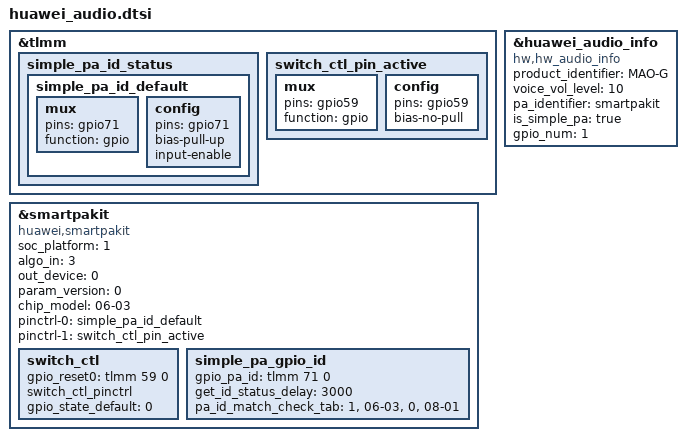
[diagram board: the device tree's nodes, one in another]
&tlmm {
	simple_pa_id_status: simple_pa_id_status {
		simple_pa_id_default: simple_pa_id_default {
			mux {
				pins = "gpio71";
				function = "gpio";
			};

			config {
				pins = "gpio71";
				bias-pull-up;
				input-enable;
			};
		};
	};
	switch_ctl_pin_active: switch_ctl_pin_active {
		mux {
			pins = "gpio59";
			function = "gpio";
		};

		config {
			pins = "gpio59";
			bias-no-pull;
		};
	};
};

&huawei_audio_info {
	compatible = "hw,hw_audio_info";
	product_identifier = "MAO-G";
	voice_vol_level = "10";
	pa_identifier = "smartpakit";
	status = "ok";
	is_simple_pa = "true";
	gpio_num = <1>; /* for simple pa vendor type GPIO*/
};

&smartpakit {
	compatible = "huawei,smartpakit";
	/* 0 hisi, 1 qcom */
	soc_platform = <1>;
	/* algo running on: 0 codec_dsp, 1 soc_dsp, 2 smartpa_dsp, 3 simple pa(not smpartpa), 4 simple pa(with i2c) */
	algo_in = <3>;
	/* algo_in params need match out_device for smartpa.
	 * Now, up to only support eight pa, so out_device = <0 0 0 0 0 0 0 0>;
	 * 1. This array is arranged in the following order:
	 *    <0 1 2 3>
	 *    <pril prir secl secr>
	 * 2. This array element value is 0 or 1:
	 *    smartpa: 0 speaker, 1 receiver
	 *    simple pa: out_device not applicable, only set 0 to indicate pa_num
	 * 3. The length of this array is variable, for example:
	 *    single pa: out_device = <0>;
	 *    two pa: out_device = <0 0>;
	 *    four pa: out_device = <1 1 0 0>;
	 *    eight pa: out_device = <0 0 0 0 0 0 0 0>; */
	out_device = <0>;
	/* param_version: 1 mixed smartpa param support */
	param_version = <0>;
	status = "ok";
	chip_model = "06-03";
	pinctrl-names = "default", "switch_ctl_active";
	pinctrl-0 = <&simple_pa_id_default>;
	pinctrl-1 = <&switch_ctl_pin_active>;

	switch_ctl {
		gpio_reset0 = <&tlmm 59 0>;
		switch_ctl_pinctrl;
		gpio_state_default = <0>;
	};

	simple_pa_gpio_id {
		gpio_pa_id = <&tlmm 71 0>;
		get_id_status_delay = <3000>;
		pa_id_match_check_tab =
			"1", "06-03",
			"0", "08-01";
	};
};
